# R40 register map
Vendor: Allwinner; Series: R40; File version: 0.1
CPU: CA7 0, little endian, MPU, FPU, double-precision FPU, 0 interrupt priority bits
Registers are 32-bit, read-write, reset 0x0 unless marked. A register's access mark holds for its fields unless they carry their own. Offsets are from the block's base; [hi:lo] are bit positions; lines under a group give offsets from that group; {n}, {i} and the like mark numbered series; 'fields as' and 'values as' point back to an identical list.

## TVD0
Base 0x01C31000
Same registers: TVD1 0x01C32000, TVD2 0x01C33000, TVD3 0x01C34000
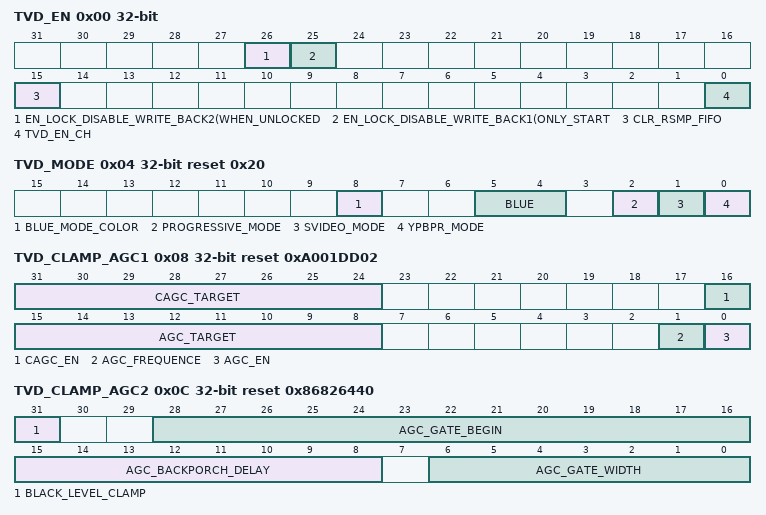
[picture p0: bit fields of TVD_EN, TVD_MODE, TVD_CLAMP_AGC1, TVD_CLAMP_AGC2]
0x00 TVD_EN — TVD Module Control Register
  [26] EN_LOCK_DISABLE_WRITE_BACK2(WHEN_UNLOCKED — en lock disable write back2(when unlocked,auto disable wb)
  [25] EN_LOCK_DISABLE_WRITE_BACK1(ONLY_START — en lock disable write back1(only start wb when locked)
  [15] CLR_RSMP_FIFO — 0: release 1: clear Set 0x1 then 0x0 to reset resample FIFO.
    0=release; 1=clear Set 0x1 then 0x0 to reset resample FIFO
  [0] TVD_EN_CH — 0:disable 1: enable
    1=enable
0x04 TVD_MODE reset 0x20 — TVD Mode Control Register
  [8] BLUE_MODE_COLOR — 0: blue 1: black
    0=blue; 1=black
  [5:4] BLUE — DISPLAY MODE 00: Disabled 01: Enabled 10: Auto 11: reserved
    0=Disabled; 1=Enabled; 2=Auto
  [2] PROGRESSIVE_MODE — 0: interlace mode 1: progressive mode
    0=interlace_mode; 1=progressive_mode
  [1] SVIDEO_MODE — 0: cvbs 1: S-Video
    0=cvbs; 1=s_Video
  [0] YPBPR_MODE — 0: Disable the component input 1: Enable the component input
    0=Disable the component input; 1=Enable the component input
0x08 TVD_CLAMP_AGC1 reset 0xA001DD02 — TVD CLAMP & AGC Control Register1
  [31:24] CAGC_TARGET — These bits set the chroma AGC target
  [16] CAGC_EN — 0: off 1: on
    0=off; 1=on
  [15:8] AGC_TARGET — When AGC_EN = 1 , the AGC_TARGET is used to directly digital AGC circuit. When AGC_EN = 0 , the AGC_TARGET is used to directly drive the analog PGA. (64 represents 1x, 32 represents 0.5x).
  [1] AGC_FREQUENCE — 0: AGC gain update once per line 1: AGC gain update once per frame
    0=AGC_gain_update_once_per_line; 1=AGC gain update once per frame
  [0] AGC_EN — 0: AGC disable 1: AGC enable
    0=AGC_disable; 1=AGC_enable
0x0C TVD_CLAMP_AGC2 reset 0x86826440 — TVD CLAMP & AGC Control Register2
  [31] BLACK_LEVEL_CLAMP — 0: subtraction 0 1: subtraction 16
    0=subtraction_0; 1=subtraction_16
  [28:16] AGC_GATE_BEGIN — Count from hsync to the next line AGC gate
  [15:8] AGC_BACKPORCH_DELAY — Count from sync tip to back porch gate
  [6:0] AGC_GATE_WIDTH
0x10 TVD_HLOCK1 reset 0x20000000 — TVD HLOCK Control Register1
  [31:0] H_SAMPLE_STEP — H_SAMPLE_STEP = F /F * 2^30
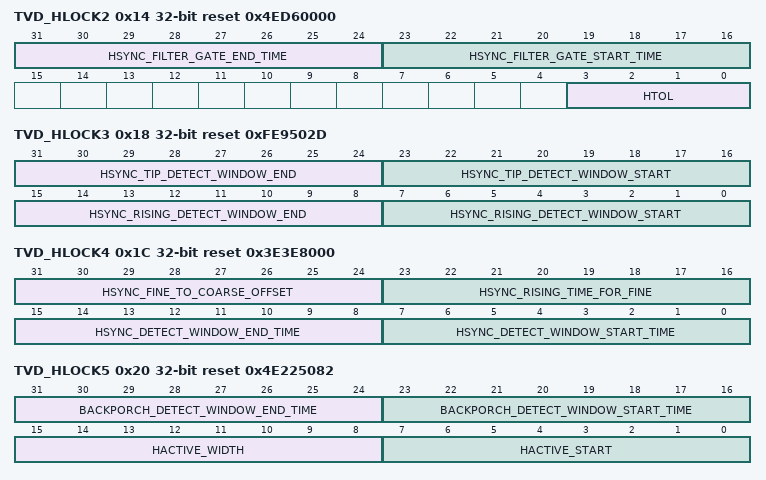
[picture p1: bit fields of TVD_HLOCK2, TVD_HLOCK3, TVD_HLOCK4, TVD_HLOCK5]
0x14 TVD_HLOCK2 reset 0x4ED60000 — TVD HLOCK Control Register2
  [31:24] HSYNC_FILTER_GATE_END_TIME — These bits specify the end of the horizontal-blank-interval window. Default = 78
  [23:16] HSYNC_FILTER_GATE_START_TIME — These bits specify the beginning of the horizontal-blank-interval window. Default = -42
  [3:0] HTOL — 0000: 858 0001: 864 0010~0111: Reserved Horizontal total pixels per line.
    0=_858; 1=864 0010~0111: Reserved Horizontal total pixels per line
0x18 TVD_HLOCK3 reset 0xFE9502D — TVD HLOCK Control Register3
  [31:24] HSYNC_TIP_DETECT_WINDOW_END — Hsync tip detect window end time
  [23:16] HSYNC_TIP_DETECT_WINDOW_START — Hsync tip detect window start time
  [15:8] HSYNC_RISING_DETECT_WINDOW_END — Hsync rising detect window end time
  [7:0] HSYNC_RISING_DETECT_WINDOW_START — Hsync rising detect window start time
0x1C TVD_HLOCK4 reset 0x3E3E8000 — TVD HLOCK Control Register4
  [31:24] HSYNC_FINE_TO_COARSE_OFFSET
  [23:16] HSYNC_RISING_TIME_FOR_FINE — Hsync rising time for fine detect
  [15:8] HSYNC_DETECT_WINDOW_END_TIME — Hsync detect window end time for corase detect
  [7:0] HSYNC_DETECT_WINDOW_START_TIME — Hsync detect window start time for coarse detection
0x20 TVD_HLOCK5 reset 0x4E225082 — TVD HLOCK Control Register5
  [31:24] BACKPORCH_DETECT_WINDOW_END_TIME, [23:16] BACKPORCH_DETECT_WINDOW_START_TIME, [15:8] HACTIVE_WIDTH, [7:0] HACTIVE_START
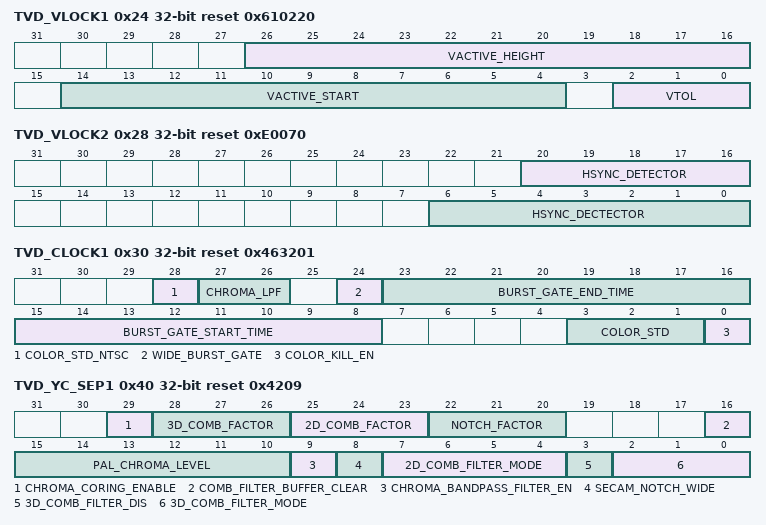
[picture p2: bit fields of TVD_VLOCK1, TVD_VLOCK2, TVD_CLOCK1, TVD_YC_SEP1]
0x24 TVD_VLOCK1 reset 0x610220 — TVD VLOCK Control Register1
  [26:16] VACTIVE_HEIGHT
  [14:4] VACTIVE_START
  [2:0] VTOL — 000: 525 line 001: 625 line
    0=_525_line; 1=_625_line
0x28 TVD_VLOCK2 reset 0xE0070 — TVD VLOCK Control Register2
  [20:16] HSYNC_DETECTOR — Hsync detector disable end line
  [6:0] HSYNC_DECTECTOR — Hsync dectector disable start line
0x30 TVD_CLOCK1 reset 0x463201 — TVD Chroma Lock Control Register1
  [28] COLOR_STD_NTSC — COLOR_STD_NTSC 0: NTSC358 1: NTSC443 Only valid when COLOR_STD set as NTSC
    0=NTSC358; 1=NTSC443 (NTSC443 Only valid when COLOR_STD set as NTSC)
  [27:26] CHROMA_LPF — CHROMA_LPF 00: Narrow 01: Middle 10: Wide 11: Reserved
    0=Narrow; 1=Middle; 2=Wide
  [24] WIDE_BURST_GATE — wide_burst_gate 0: Narrow burst gate 1: Wide burst gate
    0=Narrow burst gate; 1=Wide burst gate
  [23:16] BURST_GATE_END_TIME
  [15:8] BURST_GATE_START_TIME
  [3:1] COLOR_STD — COLOR_STD 000: NTSC 001: PAL (I,B,G,H,D,N) 010: PAL (M) 011: PAL (CN) 100: SECAM
  [0] COLOR_KILL_EN — COLOR KILL EN 1: Disable color when chroma unlock
    1=Disable color when chroma unlock
0x34 TVD_CLOCK2 reset 0x21F07C1F — TVD Chroma Lock Control Register2
  [31:0] C_SAMPLE_STEP — C_SAMPLE_STEP = F /Fin * 2^30
0x40 TVD_YC_SEP1 reset 0x4209 — TVD YC Seperation Control Register1
  [29] CHROMA_CORING_ENABLE
  [28:26] 3D_COMB_FACTOR
  [25:23] 2D_COMB_FACTOR
  [22:20] NOTCH_FACTOR
  [16] COMB_FILTER_BUFFER_CLEAR — 0: not clear 1: clear
    0=not_clear; 1=clear
  [15:10] PAL_CHROMA_LEVEL — Chroma level threshold for chroma comb filter select
  [9] CHROMA_BANDPASS_FILTER_EN
  [8] SECAM_NOTCH_WIDE — Notch bandwidth 0: narraw 1: wide
    0=narraw; 1=wide
  [7:4] 2D_COMB_FILTER_MODE — For NTSC 0000: 2D comb 0001,0010: Reserved 0011: 1D comb 0100,0101,0110,0111,1000: Reserved For PAL 0= 2D comb filter1 1= 1D comb filter1 2= 2D comb filter2 3= 1D comb filter2 4= 1D comb filter3 5=Reserved 6= 2D comb filter3 7,8= Reserved
    0=_2D (2D comb 0001,0010: Reserved); 3=_1D (1D comb 0100,0101,0110,0111,1000: Reserved For PAL 0= 2D comb filter1 1= 1D comb filter1 2= 2D comb filter2 3= 1D comb filter2 4= 1D comb filter3 5=Reserved 6= 2D comb filter3 7,8= Reserved)
  [3] 3D_COMB_FILTER_DIS — 0: Enable 3D comb filter 1: Disable 3D comb filter
    0=Enable 3D comb filter; 1=Disable 3D comb filter
  [2:0] 3D_COMB_FILTER_MODE — 000: 2D mode 001: 3D YC separation mode1 010,011: Reserved 100: 3D YC separation mode2
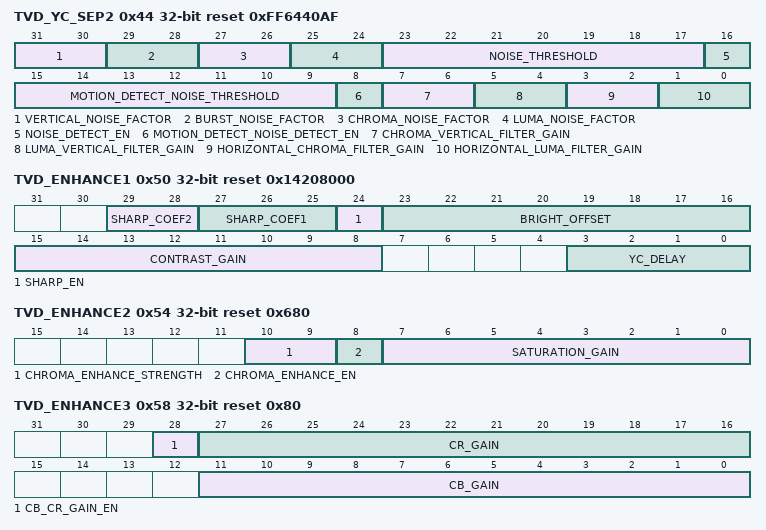
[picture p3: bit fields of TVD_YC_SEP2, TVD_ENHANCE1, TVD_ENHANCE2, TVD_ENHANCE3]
0x44 TVD_YC_SEP2 reset 0xFF6440AF — TVD YC Seperation Control Register2
  [31:30] VERTICAL_NOISE_FACTOR, [29:28] BURST_NOISE_FACTOR, [27:26] CHROMA_NOISE_FACTOR, [25:24] LUMA_NOISE_FACTOR, [23:17] NOISE_THRESHOLD, [16] NOISE_DETECT_EN, [15:9] MOTION_DETECT_NOISE_THRESHOLD, [8] MOTION_DETECT_NOISE_DETECT_EN, [7:6] CHROMA_VERTICAL_FILTER_GAIN, [5:4] LUMA_VERTICAL_FILTER_GAIN, [3:2] HORIZONTAL_CHROMA_FILTER_GAIN, [1:0] HORIZONTAL_LUMA_FILTER_GAIN
0x50 TVD_ENHANCE1 reset 0x14208000 — TVD Enhancement Control Register1
  [29:28] SHARP_COEF2
  [27:25] SHARP_COEF1 — Y = Y + YH *(SHARP_COEF1/SHARP_COEF2)
  [24] SHARP_EN — 0: Disable 1: Enable
    0=Disable; 1=Enable
  [23:16] BRIGHT_OFFSET — Set 0x00, brightness offset is -32. Set 0x20, brightness offset is 0. Set 0xFF, brightness offset is max.
  [15:8] CONTRAST_GAIN — Set 0x00, contrast gain is min. Set 0x80, contrast gain is 1. Set 0xFF, contrast gain is max.
  [3:0] YC_DELAY — 0000: Y and C no delay 0001: Y delay 1 cycle to C 0010: Y delay 2 cycle to C 0011: Y delay 3 cycle to C 0100: Y delay 4 cycle to C 0101: Y delay 5 cycle to C 0110: Y delay 6 cycle to C 0111: Y delay 7 cycle to C 1000: Reserved 1001: Reserved 1010: Reserved 1011: C delay 5 cycle to Y 1100: C delay 4 cycle to Y 1101: C delay 3 cycle to Y 1110: C delay 2 cycle to Y 1111: C delay 1 cycle to Y
    0=Y and C no delay; {v}=Y delay {v} cycle to C (v=1..7); 11=C delay 5 cycle to Y; 12=C delay 4 cycle to Y; 13=C delay 3 cycle to Y; 14=C delay 2 cycle to Y; 15=C delay 1 cycle to Y
0x54 TVD_ENHANCE2 reset 0x680 — TVD Enhancement Control Register2
  [10:9] CHROMA_ENHANCE_STRENGTH — 00: mild 01: low 10: middle 11: high
    0=mild; 1=low; 2=middle; 3=high
  [8] CHROMA_ENHANCE_EN — 0: disable 1: enable
    0=disable; 1=enable
  [7:0] SATURATION_GAIN — Set 0x00, saturation gain is min. Set 0x80, saturation gain is 1. Set 0xFF, saturation gain is max.
0x58 TVD_ENHANCE3 reset 0x80 — TVD Enhancement Control Register3
  [28] CB_CR_GAIN_EN, [27:16] CR_GAIN, [11:0] CB_GAIN
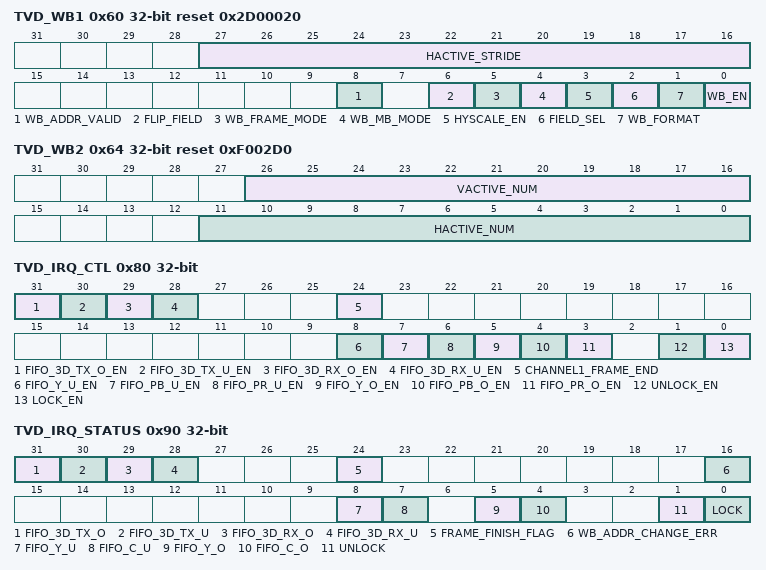
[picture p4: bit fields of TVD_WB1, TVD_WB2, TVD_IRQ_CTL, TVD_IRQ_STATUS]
0x60 TVD_WB1 reset 0x2D00020 — TVD WB DMA Control Register1
  [27:16] HACTIVE_STRIDE — Horizontal active line stride.
  [8] WB_ADDR_VALID — 0: invalid 1: valid
    0=invalid; 1=valid
  [6] FLIP_FIELD — flip_field This bit flips even/odd fields
  [5] WB_FRAME_MODE — 0: odd field or even field(desided by bit2) 1: frame
    0=odd (odd field or even field(desided by bit2)); 1=frame
  [4] WB_MB_MODE — 0: planar mode 1: mb mode
    0=planar_mode; 1=mb_mode
  [3] HYSCALE_EN
  [2] FIELD_SEL — 0: field 0 only 1: filed 1 only
    0=field 0 only; 1=filed 1 only
  [1] WB_FORMAT — 0: YUV420 1: YUV422
    0=YUV420; 1=YUV422
  [0] WB_EN — 0: disable 1: enable
    0=disable; 1=enable
0x64 TVD_WB2 reset 0xF002D0 — TVD WB DMA Control Register2
  [26:16] VACTIVE_NUM — Vertical active line number.
  [11:0] HACTIVE_NUM — Horizontal active pixel number.
0x68 TVD_WB3 — TVD WB DMA Control Register3
  [31:0] CH1_Y_ADDR
0x6C TVD_WB4 — TVD WB DMA Control Register4
  [31:0] CH1_C_ADDR
0x80 TVD_IRQ_CTL — TVD DMA Interrupt Control Register
  [31] FIFO_3D_TX_O_EN — 0: IRQ disable 1: IRQ enable
    0=IRQ_disable; 1=IRQ_enable
  [30] FIFO_3D_TX_U_EN — 0: IRQ disable 1: IRQ enable
    0=IRQ_disable; 1=IRQ_enable
  [29] FIFO_3D_RX_O_EN — 0: IRQ disable 1: IRQ enable
    0=IRQ_disable; 1=IRQ_enable
  [28] FIFO_3D_RX_U_EN — 0: IRQ disable 1: IRQ enable
    0=IRQ_disable; 1=IRQ_enable
  [24] CHANNEL1_FRAME_END
  [8] FIFO_Y_U_EN — 0: IRQ disable 1: IRQ enable
    0=IRQ_disable; 1=IRQ_enable
  [7] FIFO_PB_U_EN — 0: IRQ disable 1: IRQ enable
    0=IRQ_disable; 1=IRQ_enable
  [6] FIFO_PR_U_EN — 0: IRQ disable 1: IRQ enable
    0=IRQ_disable; 1=IRQ_enable
  [5] FIFO_Y_O_EN — 0: IRQ disable 1: IRQ enable
    0=IRQ_disable; 1=IRQ_enable
  [4] FIFO_PB_O_EN — 0: IRQ disable 1: IRQ enable
    0=IRQ_disable; 1=IRQ_enable
  [3] FIFO_PR_O_EN — 0: IRQ disable 1: IRQ enable
    0=IRQ_disable; 1=IRQ_enable
  [1] UNLOCK_EN — 0: IRQ disable 1: IRQ enable
    0=IRQ_disable; 1=IRQ_enable
  [0] LOCK_EN — 0: IRQ disable 1: IRQ enable
    0=IRQ_disable; 1=IRQ_enable
0x90 TVD_IRQ_STATUS — TVD DMA Interrupt Status Register
  [31] FIFO_3D_TX_O write-1-clears — 0: FIFO work normal 1: FIFO overflow Write 0x1 to clear this bit.
    0=FIFO work normal; 1=FIFO overflow Write 0x1 to clear this bit
  [30] FIFO_3D_TX_U write-1-clears — 0: FIFO work normal 1: FIFO underflow Write 0x1 to clear this bit.
    0=FIFO work normal; 1=FIFO underflow Write 0x1 to clear this bit
  [29] FIFO_3D_RX_O write-1-clears — 0: FIFO work normal 1: FIFO overflow Write 0x1 to clear this bit.
    values as FIFO_3D_TX_O
  [28] FIFO_3D_RX_U write-1-clears — 0: FIFO work normal 1: FIFO underflow Write 0x1 to clear this bit.
    values as FIFO_3D_TX_U
  [24] FRAME_FINISH_FLAG write-1-clears — This bit automatically set every write back frame. Set 0x1 to clear this bit.
  [16] WB_ADDR_CHANGE_ERR — Write back address change error
  [8] FIFO_Y_U write-1-clears — 0: FIFO work normal 1: FIFO underflow Write 0x1 to clear this bit.
    values as FIFO_3D_TX_U
  [7] FIFO_C_U write-1-clears — 0: FIFO work normal 1: FIFO underflow Write 0x1 to clear this bit.
    values as FIFO_3D_TX_U
  [5] FIFO_Y_O write-1-clears — 0: FIFO work normal 1: FIFO overflow Write 0x1 to clear this bit.
    values as FIFO_3D_TX_O
  [4] FIFO_C_O write-1-clears — 0: FIFO work normal 1: FIFO overflow Write 0x1 to clear this bit.
    values as FIFO_3D_TX_O
  [1] UNLOCK — 0: TVD status no change 1: TVD status change from lock to unlock
    0=TVD_status_no_change; 1=TVD status change from lock to unlock
  [0] LOCK — 0: TVD status no change 1: TVD status change from unlock to lock
    0=TVD_status_no_change; 1=TVD status change from unlock to lock
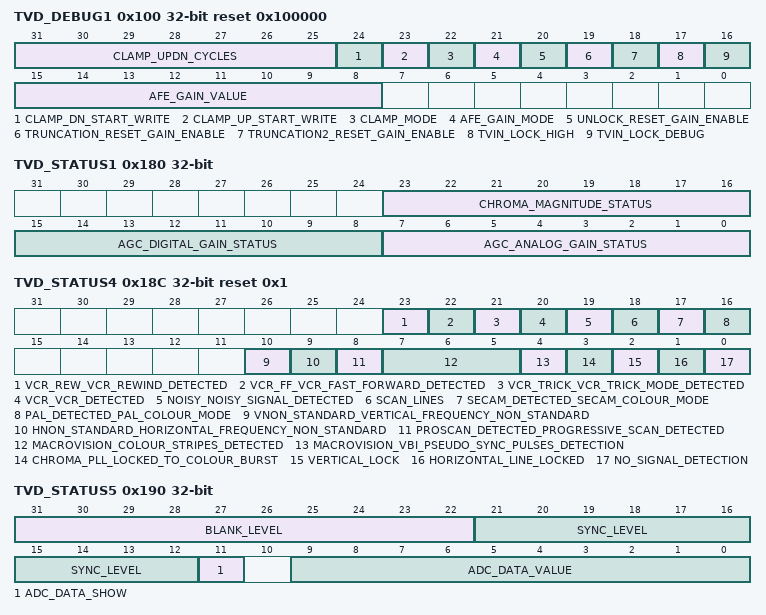
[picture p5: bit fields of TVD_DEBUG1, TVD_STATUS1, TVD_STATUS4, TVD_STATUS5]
0x100 TVD_DEBUG1 reset 0x100000 — TVD Debug Control Register1
  [31:25] CLAMP_UPDN_CYCLES
  [24] CLAMP_DN_START_WRITE — CLAMP_DN_START Write 0x1 to make clamp up, clamp up value is determined by . Note that this bit is only valid when is set as 0x1.
  [23] CLAMP_UP_START_WRITE — CLAMP_UP_START Write 0x1 to make clamp up, clamp up value is determined by . Note that this bit is only valid when is set as 0x1.
  [22] CLAMP_MODE — CLAMP_MODE 0: normal, auto clamp control 1: debug mode, clamp control by register
    0=normal, auto clamp control; 1=debug mode, clamp control by register
  [21] AFE_GAIN_MODE — AFE_GAIN_MODE 0: auto gain mode 1: debug mode, AFE gain is determined by .
    0=auto gain mode; 1=debug mode, AFE gain is determined by 
  [20] UNLOCK_RESET_GAIN_ENABLE
  [19] TRUNCATION_RESET_GAIN_ENABLE
  [18] TRUNCATION2_RESET_GAIN_ENABLE
  [17] TVIN_LOCK_HIGH
  [16] TVIN_LOCK_DEBUG
  [15:8] AFE_GAIN_VALUE
0x180 TVD_STATUS1 — TVD Debug Status Register1
  [23:16] CHROMA_MAGNITUDE_STATUS ro — These bits contain the chroma magnitude.
  [15:8] AGC_DIGITAL_GAIN_STATUS ro — These bits contain the digital AGC gain value.
  [7:0] AGC_ANALOG_GAIN_STATUS ro — These bits contain the analog AGC gain value.
0x184 TVD_STATUS2 — TVD Debug Status Register2
  [31:0] CHROMA_SYNC_DTO_INCREMENT_STATUS ro
0x188 TVD_STATUS3 — TVD Debug Status Register3
  [29:0] HORIZONTAL_SYNC_DTO_INCREMENT_STATUS ro
0x18C TVD_STATUS4 reset 0x1 — TVD Debug Status Register4
  [23] VCR_REW_VCR_REWIND_DETECTED ro
  [22] VCR_FF_VCR_FAST_FORWARD_DETECTED ro
  [21] VCR_TRICK_VCR_TRICK_MODE_DETECTED ro
  [20] VCR_VCR_DETECTED ro
  [19] NOISY_NOISY_SIGNAL_DETECTED ro — NOISY Noisy Signal Detected. This bit is set when the detected noise value (status register 7Fh) is greater than the value programmed into the `noise_thresh` register (05h).
  [18] SCAN_LINES ro — 625LINES_DETECTED 625 Scan Lines Detected
  [17] SECAM_DETECTED_SECAM_COLOUR_MODE ro — SECAM_DETECTED SECAM Colour Mode Detected
  [16] PAL_DETECTED_PAL_COLOUR_MODE ro — PAL_DETECTED PAL Colour Mode Detected
  [10] VNON_STANDARD_VERTICAL_FREQUENCY_NON_STANDARD ro — VNON_STANDARD Vertical frequency non-standard input signal Detected
  [9] HNON_STANDARD_HORIZONTAL_FREQUENCY_NON_STANDARD ro — HNON_STANDARD Horizontal frequency non-standard input signal Detected
  [8] PROSCAN_DETECTED_PROGRESSIVE_SCAN_DETECTED ro
  [7:5] MACROVISION_COLOUR_STRIPES_DETECTED ro — MACROVISION_COLOUR_STRIPES_DETECTED. The number indicates the number of colour stripe lines in each group
  [4] MACROVISION_VBI_PSEUDO_SYNC_PULSES_DETECTION ro — MACROVISION_VBI_PSEUDO-SYNC_PULSES_DETECTION 1: Detected 0: Undetected
    1=Detected; 0=Undetected
  [3] CHROMA_PLL_LOCKED_TO_COLOUR_BURST ro — CHROMA_PLL_LOCKED_TO_COLOUR_BURST 1: Locked 0: Unlocked
    1=Locked; 0=Unlocked
  [2] VERTICAL_LOCK ro — VERTICAL_LOCK 1: Locked 0: Unlocked
    1=Locked; 0=Unlocked
  [1] HORIZONTAL_LINE_LOCKED ro — HORIZONTAL_LINE_LOCKED 1: Locked 0: Unlocked
    1=Locked; 0=Unlocked
  [0] NO_SIGNAL_DETECTION ro — NO_SIGNAL_DETECTION 1: No Signal Detected 0: Signal Detected
    1=No Signal Detected; 0=Signal Detected
0x190 TVD_STATUS5 — TVD Debug Status Register5
  [31:22] BLANK_LEVEL ro, [21:12] SYNC_LEVEL ro, [11] ADC_DATA_SHOW, [9:0] ADC_DATA_VALUE ro
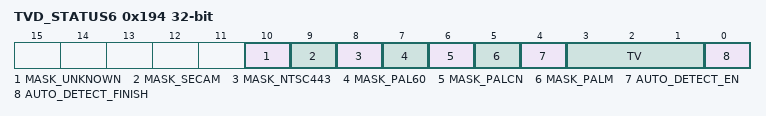
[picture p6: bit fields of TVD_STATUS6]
0x194 TVD_STATUS6 — TVD Debug Status Register6
  [10] MASK_UNKNOWN
  [9] MASK_SECAM
  [8] MASK_NTSC443
  [7] MASK_PAL60
  [6] MASK_PALCN
  [5] MASK_PALM
  [4] AUTO_DETECT_EN — 0: disable 1: enable
    0=disable; 1=enable
  [3:1] TV ro — STANDARD 001: V525_NTSC 010: V625_PAL 011: V525_PALM 100: V625_PALN 101: V525_PAL60 110: V525_NTSC443 111: V625_SECAM
    1=V525_NTSC; 2=V625_PAL; 3=V525_PALM; 4=V625_PALN; 5=V525_PAL60; 6=V525_NTSC443; 7=V625_SECAM
  [0] AUTO_DETECT_FINISH ro
